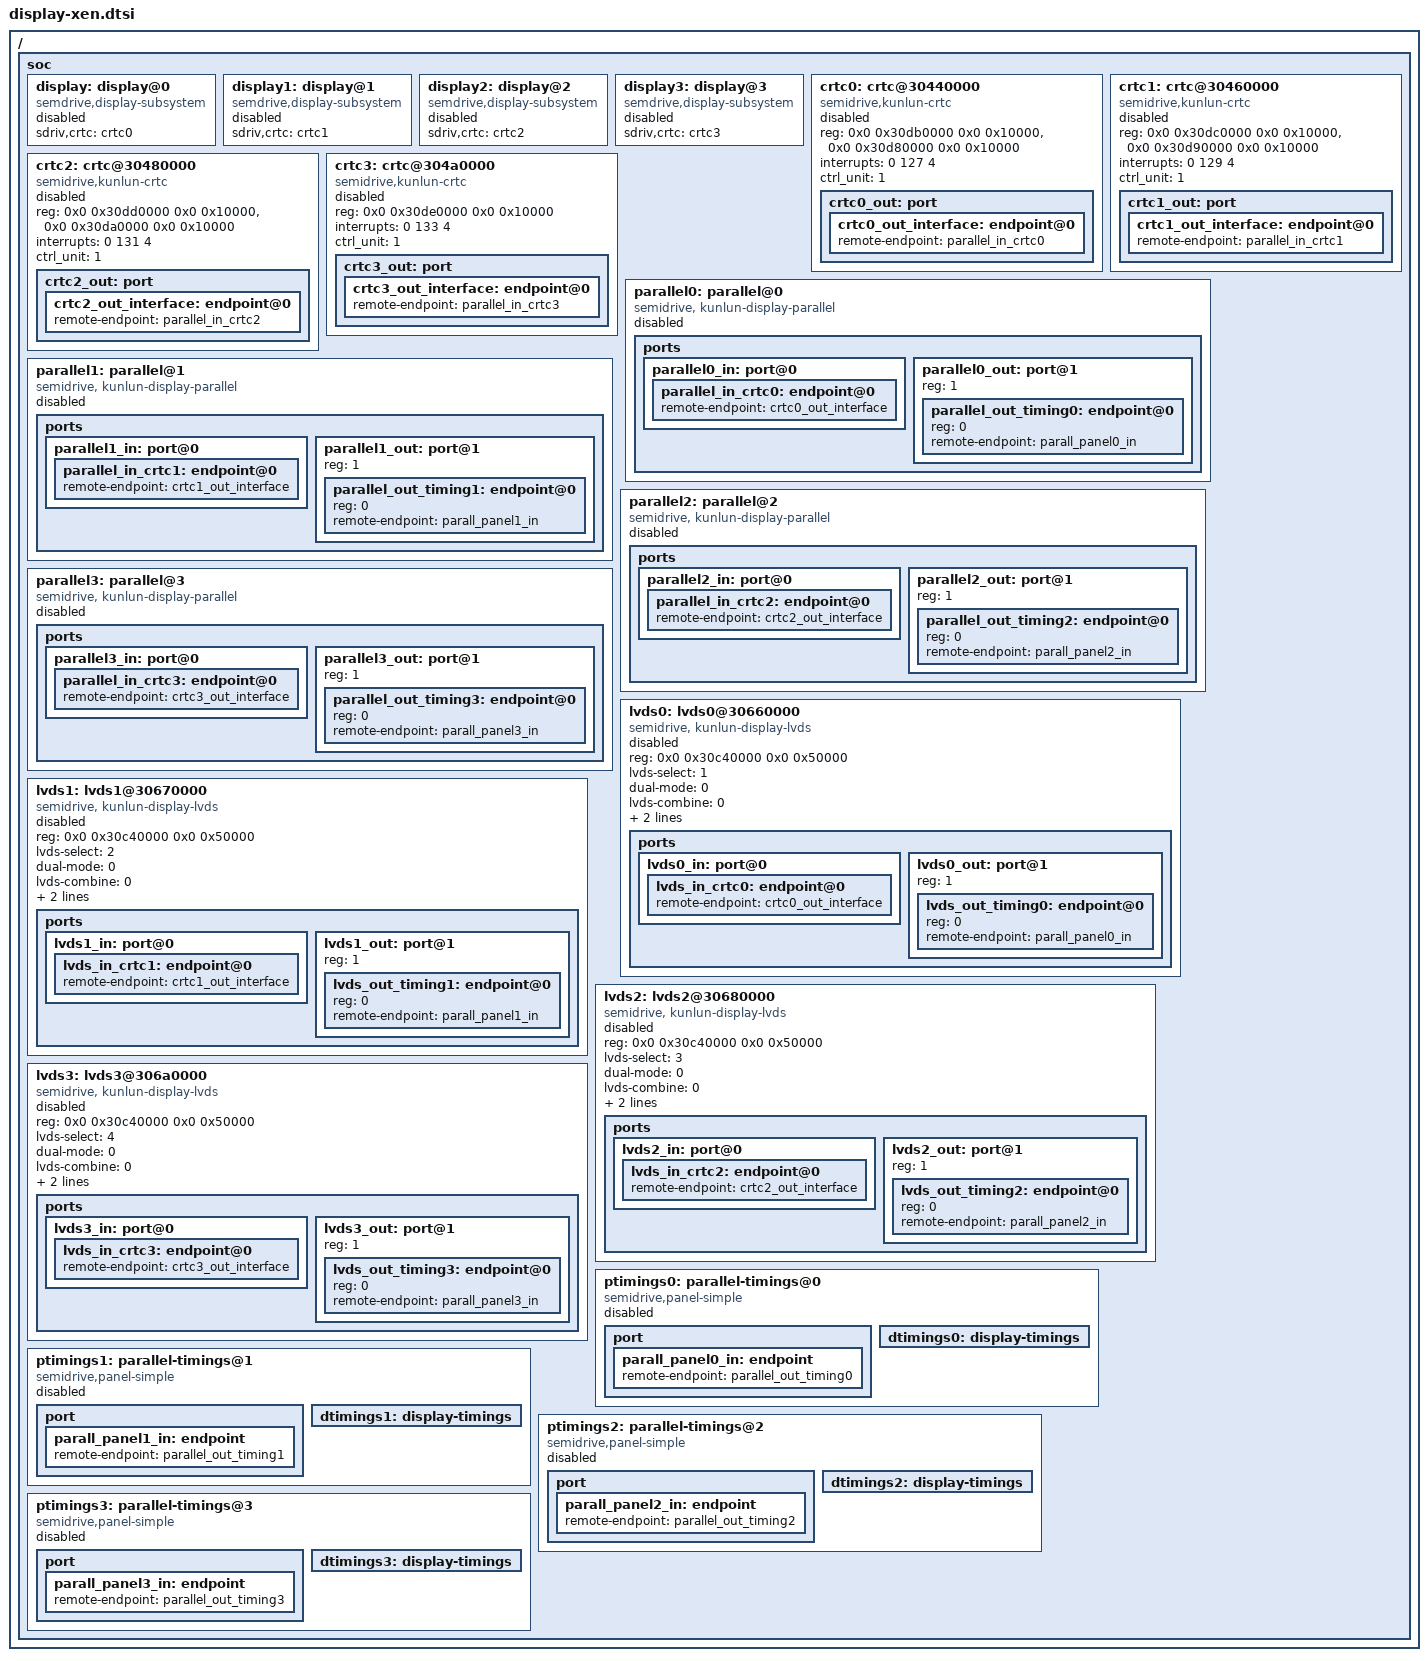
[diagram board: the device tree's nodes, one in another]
/{
        soc {
                display: display@0 {
			compatible = "semdrive,display-subsystem";
			sdriv,crtc = <&crtc0>;
			status = "disabled";
		};

		display1: display@1 {
			compatible = "semdrive,display-subsystem";
			sdriv,crtc = <&crtc1>;
			status = "disabled";
		};

                display2: display@2 {
			compatible = "semdrive,display-subsystem";
			sdriv,crtc = <&crtc2>;
			status = "disabled";
		};

                display3: display@3 {
			compatible = "semdrive,display-subsystem";
			sdriv,crtc = <&crtc3>;
			status = "disabled";
		};

		crtc0: crtc@30440000 {
			compatible = "semidrive,kunlun-crtc";
			reg-names = "dc-base", "dp-base";
			reg = <0x0 0x30db0000 0x0 0x10000>,
				<0x0 0x30d80000 0x0 0x10000>;
			interrupt-names = "dc-irq";
			interrupts = <0 127 4>;
			ctrl_unit = <1>; /*0b0001:dc, 0b0010:dp, 0b0011:dp+dc*/
			status = "disabled";

			crtc0_out: port {
				crtc0_out_interface: endpoint@0 {
					remote-endpoint = <&parallel_in_crtc0>;
				};
			};
		};

		crtc1: crtc@30460000 {
			compatible = "semidrive,kunlun-crtc";
			reg-names = "dc-base", "dp-base";
			reg = <0x0 0x30dc0000 0x0 0x10000>,
				<0x0 0x30d90000 0x0 0x10000>;
			interrupt-names = "dc-irq";
			interrupts = <0 129 4>;
			ctrl_unit = <1>; /*0b0001:dc, 0b0010:dp, 0b0011:dp+dc*/
			status = "disabled";

			crtc1_out: port {
				crtc1_out_interface: endpoint@0 {
					remote-endpoint = <&parallel_in_crtc1>;
				};
			};
		};

                crtc2: crtc@30480000 {
			compatible = "semidrive,kunlun-crtc";
			reg-names = "dc-base", "dp-base";
			reg = <0x0 0x30dd0000 0x0 0x10000>,
				<0x0 0x30da0000 0x0 0x10000>;
			interrupt-names = "dc-irq";
			interrupts = <0 131 4>;
			ctrl_unit = <1>; /*0b0001:dc, 0b0010:dp, 0b0011:dp+dc*/
			status = "disabled";

			crtc2_out: port {
				crtc2_out_interface: endpoint@0 {
					remote-endpoint = <&parallel_in_crtc2>;
				};
			};
		};

                crtc3: crtc@304a0000 {
			compatible = "semidrive,kunlun-crtc";
			reg-names = "dc-base", "dp-base";
			reg = <0x0 0x30de0000 0x0 0x10000>;
			interrupt-names = "dc-irq";
			interrupts = <0 133 4>;
			ctrl_unit = <1>; /*0b0001:dc, 0b0010:dp, 0b0011:dp+dc*/
			status = "disabled";

			crtc3_out: port {
				crtc3_out_interface: endpoint@0 {
					remote-endpoint = <&parallel_in_crtc3>;
				};
			};
		};

		parallel0: parallel@0 {
			compatible = "semidrive, kunlun-display-parallel";
			status = "disabled";

			ports {
				#address-cells = <1>;
				#size-cells = <0>;
				parallel0_in: port@0 {
					parallel_in_crtc0: endpoint@0 {
						remote-endpoint = <&crtc0_out_interface>;
					};
				};

				parallel0_out: port@1 {
					#address-cells = <1>;
					#size-cells = <0>;
					reg = <1>;
					parallel_out_timing0: endpoint@0 {
						reg = <0>;
						remote-endpoint = <&parall_panel0_in>;
					};
				};
			};
		};

		parallel1: parallel@1 {
			compatible = "semidrive, kunlun-display-parallel";
			status = "disabled";

			ports {
				#address-cells = <1>;
				#size-cells = <0>;
				parallel1_in: port@0 {
					parallel_in_crtc1: endpoint@0 {
						remote-endpoint = <&crtc1_out_interface>;
					};
				};

				parallel1_out: port@1 {
					#address-cells = <1>;
					#size-cells = <0>;
					reg = <1>;
					parallel_out_timing1: endpoint@0 {
						reg = <0>;
						remote-endpoint = <&parall_panel1_in>;
					};
				};
			};
		};

                parallel2: parallel@2 {
			compatible = "semidrive, kunlun-display-parallel";
			status = "disabled";

			ports {
				#address-cells = <1>;
				#size-cells = <0>;
				parallel2_in: port@0 {
					parallel_in_crtc2: endpoint@0 {
						remote-endpoint = <&crtc2_out_interface>;
					};
				};

				parallel2_out: port@1 {
					#address-cells = <1>;
					#size-cells = <0>;
					reg = <1>;
					parallel_out_timing2: endpoint@0 {
						reg = <0>;
						remote-endpoint = <&parall_panel2_in>;
					};
				};
			};
		};

                parallel3: parallel@3 {
			compatible = "semidrive, kunlun-display-parallel";
			status = "disabled";

			ports {
				#address-cells = <1>;
				#size-cells = <0>;
				parallel3_in: port@0 {
					parallel_in_crtc3: endpoint@0 {
						remote-endpoint = <&crtc3_out_interface>;
					};
				};

				parallel3_out: port@1 {
					#address-cells = <1>;
					#size-cells = <0>;
					reg = <1>;
					parallel_out_timing3: endpoint@0 {
						reg = <0>;
						remote-endpoint = <&parall_panel3_in>;
					};
				};
			};
		};

		lvds0: lvds0@30660000 {
			compatible = "semidrive, kunlun-display-lvds";
			reg = <0x0 0x30c40000 0x0 0x50000>;
			lvds-select = <1>;
			dual-mode = <0>;
			lvds-combine = <0>;
			map-format = <1>;
			pixel-format = <1>;

			status = "disabled";

			ports {
				#address-cells = <1>;
				#size-cells = <0>;
				lvds0_in: port@0 {
					lvds_in_crtc0: endpoint@0 {
						remote-endpoint = <&crtc0_out_interface>;
					};
				};

				lvds0_out: port@1 {
					#address-cells = <1>;
					#size-cells = <0>;
					reg = <1>;
					lvds_out_timing0: endpoint@0 {
						reg = <0>;
						remote-endpoint = <&parall_panel0_in>;
					};
				};
			};
		};

		lvds1: lvds1@30670000 {
			compatible = "semidrive, kunlun-display-lvds";
			reg = <0x0 0x30c40000 0x0 0x50000>;
			lvds-select = <2>;
			dual-mode = <0>;
			lvds-combine = <0>;
			map-format = <1>;
			pixel-format = <1>;

			status = "disabled";

			ports {
				#address-cells = <1>;
				#size-cells = <0>;
				lvds1_in: port@0 {
					lvds_in_crtc1: endpoint@0 {
						remote-endpoint = <&crtc1_out_interface>;
					};
				};

				lvds1_out: port@1 {
					#address-cells = <1>;
					#size-cells = <0>;
					reg = <1>;
					lvds_out_timing1: endpoint@0 {
						reg = <0>;
						remote-endpoint = <&parall_panel1_in>;
					};
				};
			};
		};

                lvds2: lvds2@30680000 {
			compatible = "semidrive, kunlun-display-lvds";
			reg = <0x0 0x30c40000 0x0 0x50000>;
			lvds-select = <3>;
			dual-mode = <0>;
			lvds-combine = <0>;
			map-format = <1>;
			pixel-format = <1>;

			status = "disabled";
			ports {
				#address-cells = <1>;
				#size-cells = <0>;
				lvds2_in: port@0 {
					lvds_in_crtc2: endpoint@0 {
						remote-endpoint = <&crtc2_out_interface>;
					};
				};

				lvds2_out: port@1 {
					#address-cells = <1>;
					#size-cells = <0>;
					reg = <1>;
					lvds_out_timing2: endpoint@0 {
						reg = <0>;
						remote-endpoint = <&parall_panel2_in>;
					};
				};
			};
		};

                lvds3: lvds3@306a0000 {
			compatible = "semidrive, kunlun-display-lvds";
			reg = <0x0 0x30c40000 0x0 0x50000>;
			lvds-select = <4>;
			dual-mode = <0>;
			lvds-combine = <0>;
			map-format = <1>;
			pixel-format = <1>;

			status = "disabled";
			ports {
				#address-cells = <1>;
				#size-cells = <0>;
				lvds3_in: port@0 {
					lvds_in_crtc3: endpoint@0 {
						remote-endpoint = <&crtc3_out_interface>;
					};
				};

				lvds3_out: port@1 {
					#address-cells = <1>;
					#size-cells = <0>;
					reg = <1>;
					lvds_out_timing3: endpoint@0 {
						reg = <0>;
						remote-endpoint = <&parall_panel3_in>;
					};
				};
			};
		};

                ptimings0: parallel-timings@0 {
			compatible = "semidrive,panel-simple";
			status = "disabled";

			port {
				parall_panel0_in: endpoint {
					remote-endpoint = <&parallel_out_timing0>;
				};
			};

			dtimings0: display-timings {
			};
		};

		ptimings1: parallel-timings@1 {
			compatible = "semidrive,panel-simple";
			status = "disabled";

			port {
				parall_panel1_in: endpoint {
					remote-endpoint = <&parallel_out_timing1>;
				};
			};

			dtimings1: display-timings {
			};
		};

                ptimings2: parallel-timings@2 {
			compatible = "semidrive,panel-simple";
			status = "disabled";

			port {
				parall_panel2_in: endpoint {
					remote-endpoint = <&parallel_out_timing2>;
				};
			};

			dtimings2: display-timings {
			};
		};

                ptimings3: parallel-timings@3 {
			compatible = "semidrive,panel-simple";
			status = "disabled";

			port {
				parall_panel3_in: endpoint {
					remote-endpoint = <&parallel_out_timing3>;
				};
			};

			dtimings3: display-timings {
			};
		};
        };
};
